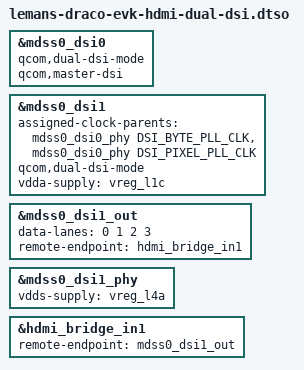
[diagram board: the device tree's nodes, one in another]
// SPDX-License-Identifier: BSD-3-Clause
/*
 * Copyright (c) Qualcomm Technologies, Inc. and/or its subsidiaries.
 */

/dts-v1/;
/plugin/;

#include <dt-bindings/clock/qcom,dsi-phy-28nm.h>

&mdss0_dsi0 {
	qcom,dual-dsi-mode;
	qcom,master-dsi;
};

&mdss0_dsi1 {
	assigned-clock-parents = <&mdss0_dsi0_phy DSI_BYTE_PLL_CLK>,
					<&mdss0_dsi0_phy DSI_PIXEL_PLL_CLK>;
	qcom,dual-dsi-mode;
	vdda-supply = <&vreg_l1c>;

	status = "okay";
};

&mdss0_dsi1_out {
	data-lanes = <0 1 2 3>;
	remote-endpoint = <&hdmi_bridge_in1>;
};

&mdss0_dsi1_phy {
	vdds-supply = <&vreg_l4a>;

	status = "okay";
};

&hdmi_bridge_in1 {
	remote-endpoint = <&mdss0_dsi1_out>;
};
